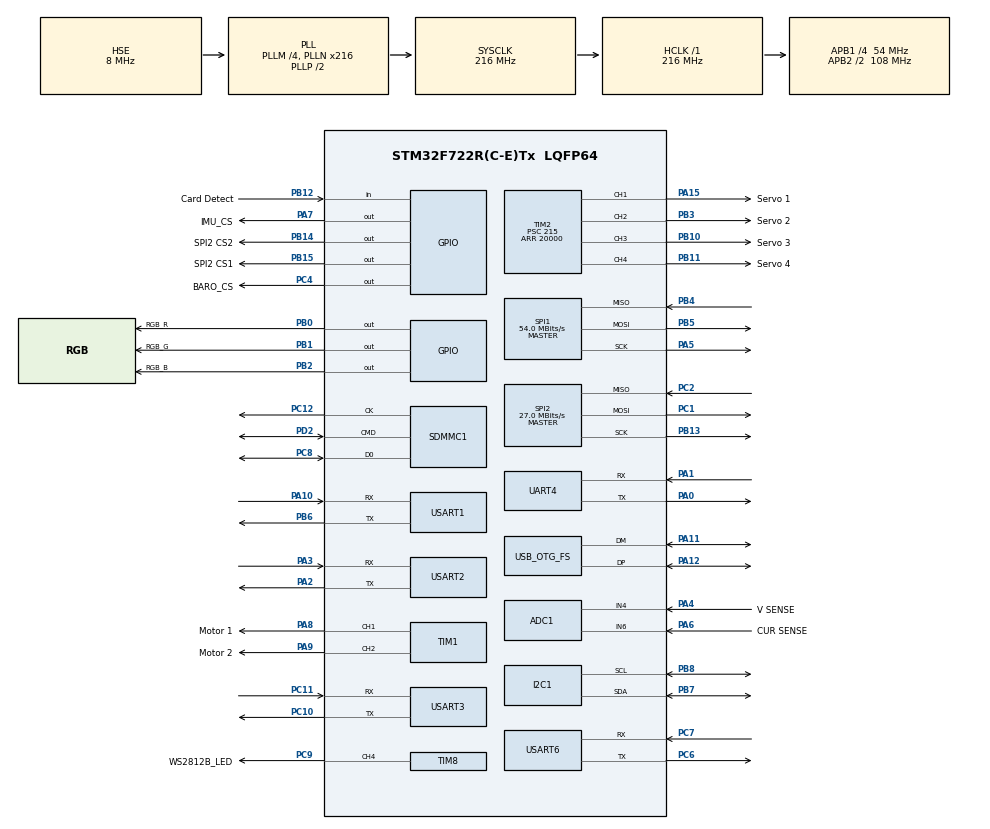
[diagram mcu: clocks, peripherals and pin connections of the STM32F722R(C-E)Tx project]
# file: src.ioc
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ADC1.Channel-1\#ChannelRegularConversion=ADC_CHANNEL_6
ADC1.NbrOfConversionFlag=1
ADC1.Rank-1\#ChannelRegularConversion=1
ADC1.SamplingTime-1\#ChannelRegularConversion=ADC_SAMPLETIME_3CYCLES
ADC1.master=1
CORTEX_M7.default_mode_Activation=1
Dma.I2C1_RX.5.Direction=DMA_PERIPH_TO_MEMORY
Dma.I2C1_RX.5.FIFOMode=DMA_FIFOMODE_DISABLE
Dma.I2C1_RX.5.Instance=DMA1_Stream0
Dma.I2C1_RX.5.MemDataAlignment=DMA_MDATAALIGN_BYTE
Dma.I2C1_RX.5.MemInc=DMA_MINC_ENABLE
Dma.I2C1_RX.5.Mode=DMA_NORMAL
Dma.I2C1_RX.5.PeriphDataAlignment=DMA_PDATAALIGN_BYTE
Dma.I2C1_RX.5.PeriphInc=DMA_PINC_DISABLE
Dma.I2C1_RX.5.Priority=DMA_PRIORITY_LOW
Dma.I2C1_TX.6.Direction=DMA_MEMORY_TO_PERIPH
Dma.I2C1_TX.6.FIFOMode=DMA_FIFOMODE_DISABLE
Dma.I2C1_TX.6.Instance=DMA1_Stream7
Dma.I2C1_TX.6.MemDataAlignment=DMA_MDATAALIGN_BYTE
Dma.I2C1_TX.6.MemInc=DMA_MINC_ENABLE
Dma.I2C1_TX.6.Mode=DMA_NORMAL
Dma.I2C1_TX.6.PeriphDataAlignment=DMA_PDATAALIGN_BYTE
Dma.I2C1_TX.6.PeriphInc=DMA_PINC_DISABLE
Dma.I2C1_TX.6.Priority=DMA_PRIORITY_LOW
Dma.Request0=TIM1_UP
Dma.Request1=USART1_RX
Dma.Request10=SPI1_TX
Dma.Request11=SPI1_RX
Dma.Request2=USART1_TX
Dma.Request3=UART4_RX
Dma.Request4=SDMMC1_TX
Dma.Request5=I2C1_RX
Dma.Request6=I2C1_TX
Dma.Request7=USART2_RX
Dma.Request8=USART2_TX
Dma.Request9=TIM8_UP
Dma.SDMMC1_TX.4.Direction=DMA_MEMORY_TO_PERIPH
Dma.SDMMC1_TX.4.FIFOMode=DMA_FIFOMODE_ENABLE
Dma.SDMMC1_TX.4.FIFOThreshold=DMA_FIFO_THRESHOLD_FULL
Dma.SDMMC1_TX.4.Instance=DMA2_Stream6
Dma.SDMMC1_TX.4.MemBurst=DMA_MBURST_INC4
Dma.SDMMC1_TX.4.MemDataAlignment=DMA_MDATAALIGN_WORD
Dma.SDMMC1_TX.4.MemInc=DMA_MINC_ENABLE
Dma.SDMMC1_TX.4.Mode=DMA_PFCTRL
Dma.SDMMC1_TX.4.PeriphBurst=DMA_PBURST_INC4
Dma.SDMMC1_TX.4.PeriphDataAlignment=DMA_PDATAALIGN_WORD
Dma.SDMMC1_TX.4.PeriphInc=DMA_PINC_DISABLE
Dma.SDMMC1_TX.4.Priority=DMA_PRIORITY_MEDIUM
Dma.SPI1_RX.11.Direction=DMA_PERIPH_TO_MEMORY
Dma.SPI1_RX.11.FIFOMode=DMA_FIFOMODE_DISABLE
Dma.SPI1_RX.11.Instance=DMA2_Stream0
Dma.SPI1_RX.11.MemDataAlignment=DMA_MDATAALIGN_BYTE
Dma.SPI1_RX.11.MemInc=DMA_MINC_ENABLE
Dma.SPI1_RX.11.Mode=DMA_NORMAL
Dma.SPI1_RX.11.PeriphDataAlignment=DMA_PDATAALIGN_BYTE
Dma.SPI1_RX.11.PeriphInc=DMA_PINC_DISABLE
Dma.SPI1_RX.11.Priority=DMA_PRIORITY_VERY_HIGH
Dma.SPI1_TX.10.Direction=DMA_MEMORY_TO_PERIPH
Dma.SPI1_TX.10.FIFOMode=DMA_FIFOMODE_DISABLE
Dma.SPI1_TX.10.Instance=DMA2_Stream3
Dma.SPI1_TX.10.MemDataAlignment=DMA_MDATAALIGN_BYTE
Dma.SPI1_TX.10.MemInc=DMA_MINC_ENABLE
Dma.SPI1_TX.10.Mode=DMA_NORMAL
Dma.SPI1_TX.10.PeriphDataAlignment=DMA_PDATAALIGN_BYTE
Dma.SPI1_TX.10.PeriphInc=DMA_PINC_DISABLE
Dma.SPI1_TX.10.Priority=DMA_PRIORITY_VERY_HIGH
Dma.TIM1_UP.0.Direction=DMA_PERIPH_TO_MEMORY
Dma.TIM1_UP.0.FIFOMode=DMA_FIFOMODE_DISABLE
Dma.TIM1_UP.0.Instance=DMA2_Stream5
Dma.TIM1_UP.0.MemDataAlignment=DMA_MDATAALIGN_HALFWORD
Dma.TIM1_UP.0.MemInc=DMA_MINC_ENABLE
Dma.TIM1_UP.0.Mode=DMA_NORMAL
Dma.TIM1_UP.0.PeriphDataAlignment=DMA_PDATAALIGN_HALFWORD
Dma.TIM1_UP.0.PeriphInc=DMA_PINC_DISABLE
Dma.TIM1_UP.0.Priority=DMA_PRIORITY_HIGH
Dma.TIM8_UP.9.Direction=DMA_PERIPH_TO_MEMORY
Dma.TIM8_UP.9.FIFOMode=DMA_FIFOMODE_DISABLE
Dma.TIM8_UP.9.Instance=DMA2_Stream1
Dma.TIM8_UP.9.MemDataAlignment=DMA_MDATAALIGN_HALFWORD
Dma.TIM8_UP.9.MemInc=DMA_MINC_ENABLE
Dma.TIM8_UP.9.Mode=DMA_NORMAL
Dma.TIM8_UP.9.PeriphDataAlignment=DMA_PDATAALIGN_HALFWORD
Dma.TIM8_UP.9.PeriphInc=DMA_PINC_DISABLE
Dma.TIM8_UP.9.Priority=DMA_PRIORITY_LOW
Dma.UART4_RX.3.Direction=DMA_PERIPH_TO_MEMORY
Dma.UART4_RX.3.FIFOMode=DMA_FIFOMODE_DISABLE
Dma.UART4_RX.3.Instance=DMA1_Stream2
Dma.UART4_RX.3.MemDataAlignment=DMA_MDATAALIGN_BYTE
Dma.UART4_RX.3.MemInc=DMA_MINC_ENABLE
Dma.UART4_RX.3.Mode=DMA_NORMAL
Dma.UART4_RX.3.PeriphDataAlignment=DMA_PDATAALIGN_BYTE
Dma.UART4_RX.3.PeriphInc=DMA_PINC_DISABLE
Dma.UART4_RX.3.Priority=DMA_PRIORITY_MEDIUM
Dma.USART1_RX.1.Direction=DMA_PERIPH_TO_MEMORY
Dma.USART1_RX.1.FIFOMode=DMA_FIFOMODE_DISABLE
Dma.USART1_RX.1.Instance=DMA2_Stream2
Dma.USART1_RX.1.MemDataAlignment=DMA_MDATAALIGN_BYTE
Dma.USART1_RX.1.MemInc=DMA_MINC_ENABLE
Dma.USART1_RX.1.Mode=DMA_NORMAL
Dma.USART1_RX.1.PeriphDataAlignment=DMA_PDATAALIGN_BYTE
Dma.USART1_RX.1.PeriphInc=DMA_PINC_DISABLE
Dma.USART1_RX.1.Priority=DMA_PRIORITY_HIGH
Dma.USART1_TX.2.Direction=DMA_MEMORY_TO_PERIPH
Dma.USART1_TX.2.FIFOMode=DMA_FIFOMODE_DISABLE
Dma.USART1_TX.2.Instance=DMA2_Stream7
Dma.USART1_TX.2.MemDataAlignment=DMA_MDATAALIGN_BYTE
Dma.USART1_TX.2.MemInc=DMA_MINC_ENABLE
Dma.USART1_TX.2.Mode=DMA_NORMAL
Dma.USART1_TX.2.PeriphDataAlignment=DMA_PDATAALIGN_BYTE
Dma.USART1_TX.2.PeriphInc=DMA_PINC_DISABLE
Dma.USART1_TX.2.Priority=DMA_PRIORITY_MEDIUM
Dma.USART2_RX.7.Direction=DMA_PERIPH_TO_MEMORY
Dma.USART2_RX.7.FIFOMode=DMA_FIFOMODE_DISABLE
Dma.USART2_RX.7.Instance=DMA1_Stream5
Dma.USART2_RX.7.MemDataAlignment=DMA_MDATAALIGN_BYTE
Dma.USART2_RX.7.MemInc=DMA_MINC_ENABLE
Dma.USART2_RX.7.Mode=DMA_NORMAL
Dma.USART2_RX.7.PeriphDataAlignment=DMA_PDATAALIGN_BYTE
Dma.USART2_RX.7.PeriphInc=DMA_PINC_DISABLE
Dma.USART2_RX.7.Priority=DMA_PRIORITY_LOW
Dma.USART2_TX.8.Direction=DMA_MEMORY_TO_PERIPH
Dma.USART2_TX.8.FIFOMode=DMA_FIFOMODE_DISABLE
Dma.USART2_TX.8.Instance=DMA1_Stream6
Dma.USART2_TX.8.MemDataAlignment=DMA_MDATAALIGN_BYTE
Dma.USART2_TX.8.MemInc=DMA_MINC_ENABLE
Dma.USART2_TX.8.Mode=DMA_NORMAL
Dma.USART2_TX.8.PeriphDataAlignment=DMA_PDATAALIGN_BYTE
Dma.USART2_TX.8.PeriphInc=DMA_PINC_DISABLE
Dma.USART2_TX.8.Priority=DMA_PRIORITY_LOW
I2C1.Timing=0x20404768
Mcu.Family=STM32F7
Mcu.Name=STM32F722R(C-E)Tx
Mcu.Package=LQFP64
NVIC.DMA1_Stream0_IRQn=true\:0\:0\:false\:false\:true\:false\:true\:true
NVIC.DMA1_Stream2_IRQn=true\:0\:0\:false\:false\:true\:false\:true\:true
NVIC.DMA1_Stream5_IRQn=true\:0\:0\:false\:false\:true\:false\:true\:true
NVIC.DMA1_Stream6_IRQn=true\:0\:0\:false\:false\:true\:false\:true\:true
NVIC.DMA1_Stream7_IRQn=true\:0\:0\:false\:false\:true\:false\:true\:true
NVIC.DMA2_Stream0_IRQn=true\:0\:0\:false\:false\:true\:false\:true\:true
NVIC.DMA2_Stream1_IRQn=true\:0\:0\:false\:false\:true\:false\:true\:true
NVIC.DMA2_Stream2_IRQn=true\:0\:0\:false\:false\:true\:false\:true\:true
NVIC.DMA2_Stream3_IRQn=true\:0\:0\:false\:false\:true\:false\:true\:true
NVIC.DMA2_Stream5_IRQn=true\:0\:0\:false\:false\:true\:false\:true\:true
NVIC.DMA2_Stream6_IRQn=true\:0\:0\:false\:false\:true\:false\:true\:true
NVIC.DMA2_Stream7_IRQn=true\:0\:0\:false\:false\:true\:false\:true\:true
NVIC.OTG_FS_IRQn=true\:0\:0\:false\:false\:true\:false\:true\:true
NVIC.PriorityGroup=NVIC_PRIORITYGROUP_4
NVIC.USART1_IRQn=true\:0\:0\:false\:false\:true\:false\:true\:true
NVIC.USART2_IRQn=true\:0\:0\:false\:false\:true\:false\:true\:true
PA0-WKUP.Mode=Asynchronous
PA0-WKUP.Signal=UART4_TX
PA1.Mode=Asynchronous
PA1.Signal=UART4_RX
PA10.Mode=Asynchronous
PA10.Signal=USART1_RX
PA11.Mode=Device_Only
PA11.Signal=USB_OTG_FS_DM
PA12.Mode=Device_Only
PA12.Signal=USB_OTG_FS_DP
PA13.Mode=Serial_Wire
PA13.Signal=SYS_JTMS-SWDIO
PA14.Mode=Serial_Wire
PA14.Signal=SYS_JTCK-SWCLK
PA15.GPIO_Label=Servo 1
PA15.Signal=S_TIM2_CH1_ETR
PA2.Mode=Asynchronous
PA2.Signal=USART2_TX
PA3.Mode=Asynchronous
PA3.Signal=USART2_RX
PA4.GPIO_Label=V SENSE
PA4.Signal=ADCx_IN4
PA5.Mode=Full_Duplex_Master
PA5.Signal=SPI1_SCK
PA6.GPIO_Label=CUR SENSE
PA6.Signal=ADCx_IN6
PA7.GPIO_Label=IMU_CS
PA7.Signal=GPIO_Output
PA8.GPIO_Label=Motor 1
PA8.Signal=S_TIM1_CH1
PA9.GPIO_Label=Motor 2
PA9.Signal=S_TIM1_CH2
PB0.GPIO_Label=RGB_R
PB0.Signal=GPIO_Output
PB1.GPIO_Label=RGB_G
PB1.Signal=GPIO_Output
PB10.GPIO_Label=Servo 3
PB10.Signal=S_TIM2_CH3
PB11.GPIO_Label=Servo 4
PB11.Signal=S_TIM2_CH4
PB12.GPIO_Label=Card Detect
PB12.Signal=GPIO_Input
PB13.Mode=Full_Duplex_Master
PB13.Signal=SPI2_SCK
PB14.GPIO_Label=SPI2 CS2
PB14.Signal=GPIO_Output
PB15.GPIO_Label=SPI2 CS1
PB15.Signal=GPIO_Output
PB2.GPIO_Label=RGB_B
PB2.Signal=GPIO_Output
PB3.GPIO_Label=Servo 2
PB3.Signal=S_TIM2_CH2
PB4.Mode=Full_Duplex_Master
PB4.Signal=SPI1_MISO
PB5.Mode=Full_Duplex_Master
PB5.Signal=SPI1_MOSI
PB6.Mode=Asynchronous
PB6.Signal=USART1_TX
PB7.Mode=I2C
PB7.Signal=I2C1_SDA
PB8.Mode=I2C
PB8.Signal=I2C1_SCL
PC1.Mode=Full_Duplex_Master
PC1.Signal=SPI2_MOSI
PC10.Mode=Asynchronous
PC10.Signal=USART3_TX
PC11.Mode=Asynchronous
PC11.Signal=USART3_RX
PC12.Mode=SD_1_bit
PC12.Signal=SDMMC1_CK
PC2.Mode=Full_Duplex_Master
PC2.Signal=SPI2_MISO
PC4.GPIO_Label=BARO_CS
PC4.Signal=GPIO_Output
PC6.Mode=Asynchronous
PC6.Signal=USART6_TX
PC7.Mode=Asynchronous
PC7.Signal=USART6_RX
PC8.Mode=SD_1_bit
PC8.Signal=SDMMC1_D0
PC9.GPIO_Label=WS2812B_LED
PC9.Signal=S_TIM8_CH4
PD2.Mode=SD_1_bit
PD2.Signal=SDMMC1_CMD
PH0-OSC_IN.Mode=HSE-External-Clock-Source
PH0-OSC_IN.Signal=RCC_OSC_IN
PH1-OSC_OUT.Mode=HSE-External-Clock-Source
PH1-OSC_OUT.Signal=RCC_OSC_OUT
ProjectManager.HeapSize=0x200
ProjectManager.StackSize=0x400
ProjectManager.TargetToolchain=CMake
RCC.AHBFreq_Value=216000000
RCC.APB1CLKDivider=RCC_HCLK_DIV4
RCC.APB1Freq_Value=54000000
RCC.APB1TimFreq_Value=108000000
RCC.APB2CLKDivider=RCC_HCLK_DIV2
RCC.APB2Freq_Value=108000000
RCC.APB2TimFreq_Value=216000000
RCC.CortexFreq_Value=216000000
RCC.EnbaleCSS=true
RCC.HCLKFreq_Value=216000000
RCC.HSE_VALUE=8000000
RCC.HSI_VALUE=16000000
RCC.LSE_VALUE=32768
RCC.PLLM=4
RCC.PLLN=216
RCC.PLLQ=9
RCC.SDMMCClockSelection=RCC_SDMMC1CLKSOURCE_CLK48
RCC.SYSCLKFreq_VALUE=216000000
RCC.SYSCLKSource=RCC_SYSCLKSOURCE_PLLCLK
RCC.USBFreq_Value=48000000
RCC.VCOOutputFreq_Value=432000000
SH.ADCx_IN4.0=ADC1_IN4,IN4
SH.ADCx_IN6.0=ADC1_IN6,IN6
SH.S_TIM1_CH1.0=TIM1_CH1,Output Compare1 CH1
SH.S_TIM1_CH2.0=TIM1_CH2,Output Compare2 CH2
SH.S_TIM2_CH1_ETR.0=TIM2_CH1,Output Compare1 CH1
SH.S_TIM2_CH2.0=TIM2_CH2,Output Compare2 CH2
SH.S_TIM2_CH3.0=TIM2_CH3,Output Compare3 CH3
SH.S_TIM2_CH4.0=TIM2_CH4,Output Compare4 CH4
SH.S_TIM8_CH4.0=TIM8_CH4,Output Compare4 CH4
SPI1.BaudRatePrescaler=SPI_BAUDRATEPRESCALER_2
SPI1.CalculateBaudRate=54.0 MBits/s
SPI1.Direction=SPI_DIRECTION_2LINES
SPI1.Mode=SPI_MODE_MASTER
SPI1.VirtualType=VM_MASTER
SPI2.BaudRatePrescaler=SPI_BAUDRATEPRESCALER_2
SPI2.CalculateBaudRate=27.0 MBits/s
SPI2.Direction=SPI_DIRECTION_2LINES
SPI2.Mode=SPI_MODE_MASTER
SPI2.VirtualType=VM_MASTER
TIM1.Channel-Output\ Compare1\ CH1=TIM_CHANNEL_1
TIM1.Channel-Output\ Compare2\ CH2=TIM_CHANNEL_2
TIM2.Channel-Output\ Compare1\ CH1=TIM_CHANNEL_1
TIM2.Channel-Output\ Compare2\ CH2=TIM_CHANNEL_2
TIM2.Channel-Output\ Compare3\ CH3=TIM_CHANNEL_3
TIM2.Channel-Output\ Compare4\ CH4=TIM_CHANNEL_4
TIM2.Period=20000
TIM2.Prescaler=215
TIM5.Prescaler=215
TIM8.Channel-Output\ Compare4\ CH4=TIM_CHANNEL_4
USART1.VirtualMode-Asynchronous=VM_ASYNC
USART2.VirtualMode-Asynchronous=VM_ASYNC
USART3.VirtualMode-Asynchronous=VM_ASYNC
USART6.VirtualMode=VM_ASYNC
USB_DEVICE.CLASS_NAME_FS=CDC
USB_DEVICE.VirtualMode-CDC_FS=Cdc
USB_DEVICE.VirtualModeFS=Cdc_FS
USB_OTG_FS.VirtualMode=Device_Only
VP_CRC_VS_CRC.Mode=CRC_Activate
VP_TIM2_VS_ClockSourceINT.Mode=Internal
VP_TIM5_VS_ClockSourceINT.Mode=Internal
VP_TIM8_VS_ClockSourceINT.Mode=Internal
VP_USB_DEVICE_VS_USB_DEVICE_CDC_FS.Mode=CDC_FS
board=custom

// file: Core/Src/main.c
/* USER CODE BEGIN Header */
/**
  ******************************************************************************
  * @file           : main.c
  * @brief          : Main program body
  ******************************************************************************
  * @attention
  *
  * Copyright (c) 2026 STMicroelectronics.
  * All rights reserved.
  *
  * This software is licensed under terms that can be found in the LICENSE file
  * in the root directory of this software component.
  * If no LICENSE file comes with this software, it is provided AS-IS.
  *
  ******************************************************************************
  */
/* USER CODE END Header */
#include "main.h"
#include "usb_device.h"

/* USER CODE BEGIN Includes */
#include "time-utils.h"
#include "sd.h"
/* USER CODE END Includes */

ADC_HandleTypeDef hadc1;

CRC_HandleTypeDef hcrc;

I2C_HandleTypeDef hi2c1;
DMA_HandleTypeDef hdma_i2c1_rx;
DMA_HandleTypeDef hdma_i2c1_tx;

SD_HandleTypeDef hsd1;
DMA_HandleTypeDef hdma_sdmmc1_tx;

SPI_HandleTypeDef hspi2;

TIM_HandleTypeDef htim1;
TIM_HandleTypeDef htim2;
TIM_HandleTypeDef htim5;
TIM_HandleTypeDef htim8;
DMA_HandleTypeDef hdma_tim1_up;
DMA_HandleTypeDef hdma_tim8_up;

UART_HandleTypeDef huart4;
UART_HandleTypeDef huart1;
UART_HandleTypeDef huart2;
UART_HandleTypeDef huart3;
UART_HandleTypeDef huart6;
DMA_HandleTypeDef hdma_uart4_rx;
DMA_HandleTypeDef hdma_usart1_rx;
DMA_HandleTypeDef hdma_usart1_tx;
DMA_HandleTypeDef hdma_usart2_rx;
DMA_HandleTypeDef hdma_usart2_tx;

void SystemClock_Config(void);
static void MPU_Config(void);
static void MX_GPIO_Init(void);
static void MX_DMA_Init(void);
static void MX_CRC_Init(void);
static void MX_I2C1_Init(void);
static void MX_SDMMC1_SD_Init(void);
static void MX_SPI1_Init(void);
static void MX_SPI2_Init(void);
static void MX_TIM1_Init(void);
static void MX_TIM2_Init(void);
static void MX_TIM5_Init(void);
static void MX_UART4_Init(void);
static void MX_USART1_UART_Init(void);
static void MX_USART2_UART_Init(void);
static void MX_USART3_UART_Init(void);
static void MX_USART6_UART_Init(void);
static void MX_ADC1_Init(void);
static void MX_TIM8_Init(void);

int main(void)
{

  /* MPU Configuration--------------------------------------------------------*/
  MPU_Config();

  /* MCU Configuration--------------------------------------------------------*/

  /* Reset of all peripherals, Initializes the Flash interface and the Systick. */
  HAL_Init();

  /* Configure the system clock */
  SystemClock_Config();

  /* Initialize all configured peripherals */
  MX_GPIO_Init();
  MX_DMA_Init();
  MX_CRC_Init();
  MX_I2C1_Init();
  MX_SDMMC1_SD_Init();
  MX_SPI1_Init();
  MX_SPI2_Init();
  MX_TIM1_Init();
  MX_TIM2_Init();
  MX_TIM5_Init();
  MX_UART4_Init();
  MX_USART1_UART_Init();
  MX_USART2_UART_Init();
  MX_USART3_UART_Init();
  MX_USART6_UART_Init();
  MX_USB_DEVICE_Init();
  MX_ADC1_Init();
  MX_TIM8_Init();
  /* USER CODE BEGIN 2 */

  TIME_UTILS_MICROS_TIM_START(&htim5);

  /* USER CODE END 2 */

  /* Infinite loop */
  /* USER CODE BEGIN WHILE */
  while (1)
  {
    uint8_t buffer[512] = {0};
    SD_READ_BLOCK(buffer, 99);
    /* USER CODE END WHILE */

  }
}

void SystemClock_Config(void)
{
  RCC_OscInitTypeDef RCC_OscInitStruct = {0};
  RCC_ClkInitTypeDef RCC_ClkInitStruct = {0};

  /** Configure the main internal regulator output voltage
  */
  __HAL_RCC_PWR_CLK_ENABLE();
  __HAL_PWR_VOLTAGESCALING_CONFIG(PWR_REGULATOR_VOLTAGE_SCALE1);

  /** Initializes the RCC Oscillators according to the specified parameters
  * in the RCC_OscInitTypeDef structure.
  */
  RCC_OscInitStruct.OscillatorType = RCC_OSCILLATORTYPE_HSE;
  RCC_OscInitStruct.HSEState = RCC_HSE_BYPASS;
  RCC_OscInitStruct.PLL.PLLState = RCC_PLL_ON;
  RCC_OscInitStruct.PLL.PLLSource = RCC_PLLSOURCE_HSE;
  RCC_OscInitStruct.PLL.PLLM = 4;
  RCC_OscInitStruct.PLL.PLLN = 216;
  RCC_OscInitStruct.PLL.PLLP = RCC_PLLP_DIV2;
  RCC_OscInitStruct.PLL.PLLQ = 9;
  if (HAL_RCC_OscConfig(&RCC_OscInitStruct) != HAL_OK)
  {
    Error_Handler();
  }

  /** Activate the Over-Drive mode
  */
  if (HAL_PWREx_EnableOverDrive() != HAL_OK)
  {
    Error_Handler();
  }

  /** Initializes the CPU, AHB and APB buses clocks
  */
  RCC_ClkInitStruct.ClockType = RCC_CLOCKTYPE_HCLK|RCC_CLOCKTYPE_SYSCLK
                              |RCC_CLOCKTYPE_PCLK1|RCC_CLOCKTYPE_PCLK2;
  RCC_ClkInitStruct.SYSCLKSource = RCC_SYSCLKSOURCE_PLLCLK;
  RCC_ClkInitStruct.AHBCLKDivider = RCC_SYSCLK_DIV1;
  RCC_ClkInitStruct.APB1CLKDivider = RCC_HCLK_DIV4;
  RCC_ClkInitStruct.APB2CLKDivider = RCC_HCLK_DIV2;

  if (HAL_RCC_ClockConfig(&RCC_ClkInitStruct, FLASH_LATENCY_7) != HAL_OK)
  {
    Error_Handler();
  }

  /** Enables the Clock Security System
  */
  HAL_RCC_EnableCSS();
}

static void MX_ADC1_Init(void)
{

  ADC_ChannelConfTypeDef sConfig = {0};

  /** Configure the global features of the ADC (Clock, Resolution, Data Alignment and number of conversion)
  */
  hadc1.Instance = ADC1;
  hadc1.Init.ClockPrescaler = ADC_CLOCK_SYNC_PCLK_DIV4;
  hadc1.Init.Resolution = ADC_RESOLUTION_12B;
  hadc1.Init.ScanConvMode = ADC_SCAN_DISABLE;
  hadc1.Init.ContinuousConvMode = DISABLE;
  hadc1.Init.DiscontinuousConvMode = DISABLE;
  hadc1.Init.ExternalTrigConvEdge = ADC_EXTERNALTRIGCONVEDGE_NONE;
  hadc1.Init.ExternalTrigConv = ADC_SOFTWARE_START;
  hadc1.Init.DataAlign = ADC_DATAALIGN_RIGHT;
  hadc1.Init.NbrOfConversion = 1;
  hadc1.Init.DMAContinuousRequests = DISABLE;
  hadc1.Init.EOCSelection = ADC_EOC_SINGLE_CONV;
  if (HAL_ADC_Init(&hadc1) != HAL_OK)
  {
    Error_Handler();
  }

  /** Configure for the selected ADC regular channel its corresponding rank in the sequencer and its sample time.
  */
  sConfig.Channel = ADC_CHANNEL_6;
  sConfig.Rank = ADC_REGULAR_RANK_1;
  sConfig.SamplingTime = ADC_SAMPLETIME_3CYCLES;
  if (HAL_ADC_ConfigChannel(&hadc1, &sConfig) != HAL_OK)
  {
    Error_Handler();
  }

}

static void MX_CRC_Init(void)
{

  hcrc.Instance = CRC;
  hcrc.Init.DefaultPolynomialUse = DEFAULT_POLYNOMIAL_ENABLE;
  hcrc.Init.DefaultInitValueUse = DEFAULT_INIT_VALUE_ENABLE;
  hcrc.Init.InputDataInversionMode = CRC_INPUTDATA_INVERSION_NONE;
  hcrc.Init.OutputDataInversionMode = CRC_OUTPUTDATA_INVERSION_DISABLE;
  hcrc.InputDataFormat = CRC_INPUTDATA_FORMAT_BYTES;
  if (HAL_CRC_Init(&hcrc) != HAL_OK)
  {
    Error_Handler();
  }

}

static void MX_I2C1_Init(void)
{

  hi2c1.Instance = I2C1;
  hi2c1.Init.Timing = 0x20404768;
  hi2c1.Init.OwnAddress1 = 0;
  hi2c1.Init.AddressingMode = I2C_ADDRESSINGMODE_7BIT;
  hi2c1.Init.DualAddressMode = I2C_DUALADDRESS_DISABLE;
  hi2c1.Init.OwnAddress2 = 0;
  hi2c1.Init.OwnAddress2Masks = I2C_OA2_NOMASK;
  hi2c1.Init.GeneralCallMode = I2C_GENERALCALL_DISABLE;
  hi2c1.Init.NoStretchMode = I2C_NOSTRETCH_DISABLE;
  if (HAL_I2C_Init(&hi2c1) != HAL_OK)
  {
    Error_Handler();
  }

  /** Configure Analogue filter
  */
  if (HAL_I2CEx_ConfigAnalogFilter(&hi2c1, I2C_ANALOGFILTER_ENABLE) != HAL_OK)
  {
    Error_Handler();
  }

  /** Configure Digital filter
  */
  if (HAL_I2CEx_ConfigDigitalFilter(&hi2c1, 0) != HAL_OK)
  {
    Error_Handler();
  }

}

static void MX_SDMMC1_SD_Init(void)
{

  hsd1.Instance = SDMMC1;
  hsd1.Init.ClockEdge = SDMMC_CLOCK_EDGE_RISING;
  hsd1.Init.ClockBypass = SDMMC_CLOCK_BYPASS_DISABLE;
  hsd1.Init.ClockPowerSave = SDMMC_CLOCK_POWER_SAVE_DISABLE;
  hsd1.Init.BusWide = SDMMC_BUS_WIDE_1B;
  hsd1.Init.HardwareFlowControl = SDMMC_HARDWARE_FLOW_CONTROL_DISABLE;
  hsd1.Init.ClockDiv = 0;
  if (HAL_SD_Init(&hsd1) != HAL_OK)
  {
    Error_Handler();
  }

}

static void MX_SPI1_Init(void)
{

  LL_SPI_InitTypeDef SPI_InitStruct = {0};

  LL_GPIO_InitTypeDef GPIO_InitStruct = {0};

  /* Peripheral clock enable */
  LL_APB2_GRP1_EnableClock(LL_APB2_GRP1_PERIPH_SPI1);

  LL_AHB1_GRP1_EnableClock(LL_AHB1_GRP1_PERIPH_GPIOA);
  LL_AHB1_GRP1_EnableClock(LL_AHB1_GRP1_PERIPH_GPIOB);
  /**SPI1 GPIO Configuration
  PA5   ------> SPI1_SCK
  PB4   ------> SPI1_MISO
  PB5   ------> SPI1_MOSI
  */
  GPIO_InitStruct.Pin = LL_GPIO_PIN_5;
  GPIO_InitStruct.Mode = LL_GPIO_MODE_ALTERNATE;
  GPIO_InitStruct.Speed = LL_GPIO_SPEED_FREQ_VERY_HIGH;
  GPIO_InitStruct.OutputType = LL_GPIO_OUTPUT_PUSHPULL;
  GPIO_InitStruct.Pull = LL_GPIO_PULL_NO;
  GPIO_InitStruct.Alternate = LL_GPIO_AF_5;
  LL_GPIO_Init(GPIOA, &GPIO_InitStruct);

  GPIO_InitStruct.Pin = LL_GPIO_PIN_4;
  GPIO_InitStruct.Mode = LL_GPIO_MODE_ALTERNATE;
  GPIO_InitStruct.Speed = LL_GPIO_SPEED_FREQ_VERY_HIGH;
  GPIO_InitStruct.OutputType = LL_GPIO_OUTPUT_PUSHPULL;
  GPIO_InitStruct.Pull = LL_GPIO_PULL_NO;
  GPIO_InitStruct.Alternate = LL_GPIO_AF_5;
  LL_GPIO_Init(GPIOB, &GPIO_InitStruct);

  GPIO_InitStruct.Pin = LL_GPIO_PIN_5;
  GPIO_InitStruct.Mode = LL_GPIO_MODE_ALTERNATE;
  GPIO_InitStruct.Speed = LL_GPIO_SPEED_FREQ_VERY_HIGH;
  GPIO_InitStruct.OutputType = LL_GPIO_OUTPUT_PUSHPULL;
  GPIO_InitStruct.Pull = LL_GPIO_PULL_NO;
  GPIO_InitStruct.Alternate = LL_GPIO_AF_5;
  LL_GPIO_Init(GPIOB, &GPIO_InitStruct);

  /* SPI1 DMA Init */

  /* SPI1_TX Init */
  LL_DMA_SetChannelSelection(DMA2, LL_DMA_STREAM_3, LL_DMA_CHANNEL_3);

  LL_DMA_SetDataTransferDirection(DMA2, LL_DMA_STREAM_3, LL_DMA_DIRECTION_MEMORY_TO_PERIPH);

  LL_DMA_SetStreamPriorityLevel(DMA2, LL_DMA_STREAM_3, LL_DMA_PRIORITY_VERYHIGH);

  LL_DMA_SetMode(DMA2, LL_DMA_STREAM_3, LL_DMA_MODE_NORMAL);

  LL_DMA_SetPeriphIncMode(DMA2, LL_DMA_STREAM_3, LL_DMA_PERIPH_NOINCREMENT);

  LL_DMA_SetMemoryIncMode(DMA2, LL_DMA_STREAM_3, LL_DMA_MEMORY_INCREMENT);

  LL_DMA_SetPeriphSize(DMA2, LL_DMA_STREAM_3, LL_DMA_PDATAALIGN_BYTE);

  LL_DMA_SetMemorySize(DMA2, LL_DMA_STREAM_3, LL_DMA_MDATAALIGN_BYTE);

  LL_DMA_DisableFifoMode(DMA2, LL_DMA_STREAM_3);

  /* SPI1_RX Init */
  LL_DMA_SetChannelSelection(DMA2, LL_DMA_STREAM_0, LL_DMA_CHANNEL_3);

  LL_DMA_SetDataTransferDirection(DMA2, LL_DMA_STREAM_0, LL_DMA_DIRECTION_PERIPH_TO_MEMORY);

  LL_DMA_SetStreamPriorityLevel(DMA2, LL_DMA_STREAM_0, LL_DMA_PRIORITY_VERYHIGH);

  LL_DMA_SetMode(DMA2, LL_DMA_STREAM_0, LL_DMA_MODE_NORMAL);

  LL_DMA_SetPeriphIncMode(DMA2, LL_DMA_STREAM_0, LL_DMA_PERIPH_NOINCREMENT);

  LL_DMA_SetMemoryIncMode(DMA2, LL_DMA_STREAM_0, LL_DMA_MEMORY_INCREMENT);

  LL_DMA_SetPeriphSize(DMA2, LL_DMA_STREAM_0, LL_DMA_PDATAALIGN_BYTE);

  LL_DMA_SetMemorySize(DMA2, LL_DMA_STREAM_0, LL_DMA_MDATAALIGN_BYTE);

  LL_DMA_DisableFifoMode(DMA2, LL_DMA_STREAM_0);

  /* SPI1 parameter configuration*/
  SPI_InitStruct.TransferDirection = LL_SPI_FULL_DUPLEX;
  SPI_InitStruct.Mode = LL_SPI_MODE_MASTER;
  SPI_InitStruct.DataWidth = LL_SPI_DATAWIDTH_4BIT;
  SPI_InitStruct.ClockPolarity = LL_SPI_POLARITY_LOW;
  SPI_InitStruct.ClockPhase = LL_SPI_PHASE_1EDGE;
  SPI_InitStruct.NSS = LL_SPI_NSS_SOFT;
  SPI_InitStruct.BaudRate = LL_SPI_BAUDRATEPRESCALER_DIV2;
  SPI_InitStruct.BitOrder = LL_SPI_MSB_FIRST;
  SPI_InitStruct.CRCCalculation = LL_SPI_CRCCALCULATION_DISABLE;
  SPI_InitStruct.CRCPoly = 7;
  LL_SPI_Init(SPI1, &SPI_InitStruct);
  LL_SPI_SetStandard(SPI1, LL_SPI_PROTOCOL_MOTOROLA);
  LL_SPI_EnableNSSPulseMgt(SPI1);

}

static void MX_SPI2_Init(void)
{

  /* SPI2 parameter configuration*/
  hspi2.Instance = SPI2;
  hspi2.Init.Mode = SPI_MODE_MASTER;
  hspi2.Init.Direction = SPI_DIRECTION_2LINES;
  hspi2.Init.DataSize = SPI_DATASIZE_4BIT;
  hspi2.Init.CLKPolarity = SPI_POLARITY_LOW;
  hspi2.Init.CLKPhase = SPI_PHASE_1EDGE;
  hspi2.Init.NSS = SPI_NSS_SOFT;
  hspi2.Init.BaudRatePrescaler = SPI_BAUDRATEPRESCALER_2;
  hspi2.Init.FirstBit = SPI_FIRSTBIT_MSB;
  hspi2.Init.TIMode = SPI_TIMODE_DISABLE;
  hspi2.Init.CRCCalculation = SPI_CRCCALCULATION_DISABLE;
  hspi2.Init.CRCPolynomial = 7;
  hspi2.Init.CRCLength = SPI_CRC_LENGTH_DATASIZE;
  hspi2.Init.NSSPMode = SPI_NSS_PULSE_ENABLE;
  if (HAL_SPI_Init(&hspi2) != HAL_OK)
  {
    Error_Handler();
  }

}

static void MX_TIM1_Init(void)
{

  TIM_MasterConfigTypeDef sMasterConfig = {0};
  TIM_OC_InitTypeDef sConfigOC = {0};
  TIM_BreakDeadTimeConfigTypeDef sBreakDeadTimeConfig = {0};

  htim1.Instance = TIM1;
  htim1.Init.Prescaler = 0;
  htim1.Init.CounterMode = TIM_COUNTERMODE_UP;
  htim1.Init.Period = 65535;
  htim1.Init.ClockDivision = TIM_CLOCKDIVISION_DIV1;
  htim1.Init.RepetitionCounter = 0;
  htim1.Init.AutoReloadPreload = TIM_AUTORELOAD_PRELOAD_DISABLE;
  if (HAL_TIM_OC_Init(&htim1) != HAL_OK)
  {
    Error_Handler();
  }
  sMasterConfig.MasterOutputTrigger = TIM_TRGO_RESET;
  sMasterConfig.MasterOutputTrigger2 = TIM_TRGO2_RESET;
  sMasterConfig.MasterSlaveMode = TIM_MASTERSLAVEMODE_DISABLE;
  if (HAL_TIMEx_MasterConfigSynchronization(&htim1, &sMasterConfig) != HAL_OK)
  {
    Error_Handler();
  }
  sConfigOC.OCMode = TIM_OCMODE_TIMING;
  sConfigOC.Pulse = 0;
  sConfigOC.OCPolarity = TIM_OCPOLARITY_HIGH;
  sConfigOC.OCNPolarity = TIM_OCNPOLARITY_HIGH;
  sConfigOC.OCFastMode = TIM_OCFAST_DISABLE;
  sConfigOC.OCIdleState = TIM_OCIDLESTATE_RESET;
  sConfigOC.OCNIdleState = TIM_OCNIDLESTATE_RESET;
  if (HAL_TIM_OC_ConfigChannel(&htim1, &sConfigOC, TIM_CHANNEL_1) != HAL_OK)
  {
    Error_Handler();
  }
  if (HAL_TIM_OC_ConfigChannel(&htim1, &sConfigOC, TIM_CHANNEL_2) != HAL_OK)
  {
    Error_Handler();
  }
  sBreakDeadTimeConfig.OffStateRunMode = TIM_OSSR_DISABLE;
  sBreakDeadTimeConfig.OffStateIDLEMode = TIM_OSSI_DISABLE;
  sBreakDeadTimeConfig.LockLevel = TIM_LOCKLEVEL_OFF;
  sBreakDeadTimeConfig.DeadTime = 0;
  sBreakDeadTimeConfig.BreakState = TIM_BREAK_DISABLE;
  sBreakDeadTimeConfig.BreakPolarity = TIM_BREAKPOLARITY_HIGH;
  sBreakDeadTimeConfig.BreakFilter = 0;
  sBreakDeadTimeConfig.Break2State = TIM_BREAK2_DISABLE;
  sBreakDeadTimeConfig.Break2Polarity = TIM_BREAK2POLARITY_HIGH;
  sBreakDeadTimeConfig.Break2Filter = 0;
  sBreakDeadTimeConfig.AutomaticOutput = TIM_AUTOMATICOUTPUT_DISABLE;
  if (HAL_TIMEx_ConfigBreakDeadTime(&htim1, &sBreakDeadTimeConfig) != HAL_OK)
  {
    Error_Handler();
  }
  HAL_TIM_MspPostInit(&htim1);

}

static void MX_TIM2_Init(void)
{

  TIM_ClockConfigTypeDef sClockSourceConfig = {0};
  TIM_MasterConfigTypeDef sMasterConfig = {0};
  TIM_OC_InitTypeDef sConfigOC = {0};

  htim2.Instance = TIM2;
  htim2.Init.Prescaler = 215;
  htim2.Init.CounterMode = TIM_COUNTERMODE_UP;
  htim2.Init.Period = 20000;
  htim2.Init.ClockDivision = TIM_CLOCKDIVISION_DIV1;
  htim2.Init.AutoReloadPreload = TIM_AUTORELOAD_PRELOAD_DISABLE;
  if (HAL_TIM_Base_Init(&htim2) != HAL_OK)
  {
    Error_Handler();
  }
  sClockSourceConfig.ClockSource = TIM_CLOCKSOURCE_INTERNAL;
  if (HAL_TIM_ConfigClockSource(&htim2, &sClockSourceConfig) != HAL_OK)
  {
    Error_Handler();
  }
  if (HAL_TIM_OC_Init(&htim2) != HAL_OK)
  {
    Error_Handler();
  }
  sMasterConfig.MasterOutputTrigger = TIM_TRGO_RESET;
  sMasterConfig.MasterSlaveMode = TIM_MASTERSLAVEMODE_DISABLE;
  if (HAL_TIMEx_MasterConfigSynchronization(&htim2, &sMasterConfig) != HAL_OK)
  {
    Error_Handler();
  }
  sConfigOC.OCMode = TIM_OCMODE_TIMING;
  sConfigOC.Pulse = 0;
  sConfigOC.OCPolarity = TIM_OCPOLARITY_HIGH;
  sConfigOC.OCFastMode = TIM_OCFAST_DISABLE;
  if (HAL_TIM_OC_ConfigChannel(&htim2, &sConfigOC, TIM_CHANNEL_1) != HAL_OK)
  {
    Error_Handler();
  }
  if (HAL_TIM_OC_ConfigChannel(&htim2, &sConfigOC, TIM_CHANNEL_2) != HAL_OK)
  {
    Error_Handler();
  }
  if (HAL_TIM_OC_ConfigChannel(&htim2, &sConfigOC, TIM_CHANNEL_3) != HAL_OK)
  {
    Error_Handler();
  }
  if (HAL_TIM_OC_ConfigChannel(&htim2, &sConfigOC, TIM_CHANNEL_4) != HAL_OK)
  {
    Error_Handler();
  }
  HAL_TIM_MspPostInit(&htim2);

}

static void MX_TIM5_Init(void)
{

  TIM_ClockConfigTypeDef sClockSourceConfig = {0};
  TIM_MasterConfigTypeDef sMasterConfig = {0};

  htim5.Instance = TIM5;
  htim5.Init.Prescaler = 215;
  htim5.Init.CounterMode = TIM_COUNTERMODE_UP;
  htim5.Init.Period = 4294967295;
  htim5.Init.ClockDivision = TIM_CLOCKDIVISION_DIV1;
  htim5.Init.AutoReloadPreload = TIM_AUTORELOAD_PRELOAD_DISABLE;
  if (HAL_TIM_Base_Init(&htim5) != HAL_OK)
  {
    Error_Handler();
  }
  sClockSourceConfig.ClockSource = TIM_CLOCKSOURCE_INTERNAL;
  if (HAL_TIM_ConfigClockSource(&htim5, &sClockSourceConfig) != HAL_OK)
  {
    Error_Handler();
  }
  sMasterConfig.MasterOutputTrigger = TIM_TRGO_RESET;
  sMasterConfig.MasterSlaveMode = TIM_MASTERSLAVEMODE_DISABLE;
  if (HAL_TIMEx_MasterConfigSynchronization(&htim5, &sMasterConfig) != HAL_OK)
  {
    Error_Handler();
  }

}

static void MX_TIM8_Init(void)
{

  TIM_ClockConfigTypeDef sClockSourceConfig = {0};
  TIM_MasterConfigTypeDef sMasterConfig = {0};
  TIM_OC_InitTypeDef sConfigOC = {0};
  TIM_BreakDeadTimeConfigTypeDef sBreakDeadTimeConfig = {0};

  htim8.Instance = TIM8;
  htim8.Init.Prescaler = 0;
  htim8.Init.CounterMode = TIM_COUNTERMODE_UP;
  htim8.Init.Period = 65535;
  htim8.Init.ClockDivision = TIM_CLOCKDIVISION_DIV1;
  htim8.Init.RepetitionCounter = 0;
  htim8.Init.AutoReloadPreload = TIM_AUTORELOAD_PRELOAD_DISABLE;
  if (HAL_TIM_Base_Init(&htim8) != HAL_OK)
  {
    Error_Handler();
  }
  sClockSourceConfig.ClockSource = TIM_CLOCKSOURCE_INTERNAL;
  if (HAL_TIM_ConfigClockSource(&htim8, &sClockSourceConfig) != HAL_OK)
  {
    Error_Handler();
  }
  if (HAL_TIM_OC_Init(&htim8) != HAL_OK)
  {
    Error_Handler();
  }
  sMasterConfig.MasterOutputTrigger = TIM_TRGO_RESET;
  sMasterConfig.MasterOutputTrigger2 = TIM_TRGO2_RESET;
  sMasterConfig.MasterSlaveMode = TIM_MASTERSLAVEMODE_DISABLE;
  if (HAL_TIMEx_MasterConfigSynchronization(&htim8, &sMasterConfig) != HAL_OK)
  {
    Error_Handler();
  }
  sConfigOC.OCMode = TIM_OCMODE_TIMING;
  sConfigOC.Pulse = 0;
  sConfigOC.OCPolarity = TIM_OCPOLARITY_HIGH;
  sConfigOC.OCFastMode = TIM_OCFAST_DISABLE;
  sConfigOC.OCIdleState = TIM_OCIDLESTATE_RESET;
  sConfigOC.OCNIdleState = TIM_OCNIDLESTATE_RESET;
  if (HAL_TIM_OC_ConfigChannel(&htim8, &sConfigOC, TIM_CHANNEL_4) != HAL_OK)
  {
    Error_Handler();
  }
  sBreakDeadTimeConfig.OffStateRunMode = TIM_OSSR_DISABLE;
  sBreakDeadTimeConfig.OffStateIDLEMode = TIM_OSSI_DISABLE;
  sBreakDeadTimeConfig.LockLevel = TIM_LOCKLEVEL_OFF;
  sBreakDeadTimeConfig.DeadTime = 0;
  sBreakDeadTimeConfig.BreakState = TIM_BREAK_DISABLE;
  sBreakDeadTimeConfig.BreakPolarity = TIM_BREAKPOLARITY_HIGH;
  sBreakDeadTimeConfig.BreakFilter = 0;
  sBreakDeadTimeConfig.Break2State = TIM_BREAK2_DISABLE;
  sBreakDeadTimeConfig.Break2Polarity = TIM_BREAK2POLARITY_HIGH;
  sBreakDeadTimeConfig.Break2Filter = 0;
  sBreakDeadTimeConfig.AutomaticOutput = TIM_AUTOMATICOUTPUT_DISABLE;
  if (HAL_TIMEx_ConfigBreakDeadTime(&htim8, &sBreakDeadTimeConfig) != HAL_OK)
  {
    Error_Handler();
  }
  HAL_TIM_MspPostInit(&htim8);

}

static void MX_UART4_Init(void)
{

  huart4.Instance = UART4;
  huart4.Init.BaudRate = 115200;
  huart4.Init.WordLength = UART_WORDLENGTH_8B;
  huart4.Init.StopBits = UART_STOPBITS_1;
  huart4.Init.Parity = UART_PARITY_NONE;
  huart4.Init.Mode = UART_MODE_TX_RX;
  huart4.Init.HwFlowCtl = UART_HWCONTROL_NONE;
  huart4.Init.OverSampling = UART_OVERSAMPLING_16;
  huart4.Init.OneBitSampling = UART_ONE_BIT_SAMPLE_DISABLE;
  huart4.AdvancedInit.AdvFeatureInit = UART_ADVFEATURE_NO_INIT;
  if (HAL_UART_Init(&huart4) != HAL_OK)
  {
    Error_Handler();
  }

}

static void MX_USART1_UART_Init(void)
{

  huart1.Instance = USART1;
  huart1.Init.BaudRate = 115200;
  huart1.Init.WordLength = UART_WORDLENGTH_8B;
  huart1.Init.StopBits = UART_STOPBITS_1;
  huart1.Init.Parity = UART_PARITY_NONE;
  huart1.Init.Mode = UART_MODE_TX_RX;
  huart1.Init.HwFlowCtl = UART_HWCONTROL_NONE;
  huart1.Init.OverSampling = UART_OVERSAMPLING_16;
  huart1.Init.OneBitSampling = UART_ONE_BIT_SAMPLE_DISABLE;
  huart1.AdvancedInit.AdvFeatureInit = UART_ADVFEATURE_NO_INIT;
  if (HAL_UART_Init(&huart1) != HAL_OK)
  {
    Error_Handler();
  }

}

static void MX_USART2_UART_Init(void)
{

  huart2.Instance = USART2;
  huart2.Init.BaudRate = 115200;
  huart2.Init.WordLength = UART_WORDLENGTH_8B;
  huart2.Init.StopBits = UART_STOPBITS_1;
  huart2.Init.Parity = UART_PARITY_NONE;
  huart2.Init.Mode = UART_MODE_TX_RX;
  huart2.Init.HwFlowCtl = UART_HWCONTROL_NONE;
  huart2.Init.OverSampling = UART_OVERSAMPLING_16;
  huart2.Init.OneBitSampling = UART_ONE_BIT_SAMPLE_DISABLE;
  huart2.AdvancedInit.AdvFeatureInit = UART_ADVFEATURE_NO_INIT;
  if (HAL_UART_Init(&huart2) != HAL_OK)
  {
    Error_Handler();
  }

}

static void MX_USART3_UART_Init(void)
{

  huart3.Instance = USART3;
  huart3.Init.BaudRate = 115200;
  huart3.Init.WordLength = UART_WORDLENGTH_8B;
  huart3.Init.StopBits = UART_STOPBITS_1;
  huart3.Init.Parity = UART_PARITY_NONE;
  huart3.Init.Mode = UART_MODE_TX_RX;
  huart3.Init.HwFlowCtl = UART_HWCONTROL_NONE;
  huart3.Init.OverSampling = UART_OVERSAMPLING_16;
  huart3.Init.OneBitSampling = UART_ONE_BIT_SAMPLE_DISABLE;
  huart3.AdvancedInit.AdvFeatureInit = UART_ADVFEATURE_NO_INIT;
  if (HAL_UART_Init(&huart3) != HAL_OK)
  {
    Error_Handler();
  }

}

static void MX_USART6_UART_Init(void)
{

  huart6.Instance = USART6;
  huart6.Init.BaudRate = 115200;
  huart6.Init.WordLength = UART_WORDLENGTH_8B;
  huart6.Init.StopBits = UART_STOPBITS_1;
  huart6.Init.Parity = UART_PARITY_NONE;
  huart6.Init.Mode = UART_MODE_TX_RX;
  huart6.Init.HwFlowCtl = UART_HWCONTROL_NONE;
  huart6.Init.OverSampling = UART_OVERSAMPLING_16;
  huart6.Init.OneBitSampling = UART_ONE_BIT_SAMPLE_DISABLE;
  huart6.AdvancedInit.AdvFeatureInit = UART_ADVFEATURE_NO_INIT;
  if (HAL_UART_Init(&huart6) != HAL_OK)
  {
    Error_Handler();
  }

}

static void MX_DMA_Init(void)
{

  /* DMA controller clock enable */
  __HAL_RCC_DMA2_CLK_ENABLE();
  __HAL_RCC_DMA1_CLK_ENABLE();

  /* DMA interrupt init */
  /* DMA1_Stream0_IRQn interrupt configuration */
  HAL_NVIC_SetPriority(DMA1_Stream0_IRQn, 0, 0);
  HAL_NVIC_EnableIRQ(DMA1_Stream0_IRQn);
  /* DMA1_Stream2_IRQn interrupt configuration */
  HAL_NVIC_SetPriority(DMA1_Stream2_IRQn, 0, 0);
  HAL_NVIC_EnableIRQ(DMA1_Stream2_IRQn);
  /* DMA1_Stream5_IRQn interrupt configuration */
  HAL_NVIC_SetPriority(DMA1_Stream5_IRQn, 0, 0);
  HAL_NVIC_EnableIRQ(DMA1_Stream5_IRQn);
  /* DMA1_Stream6_IRQn interrupt configuration */
  HAL_NVIC_SetPriority(DMA1_Stream6_IRQn, 0, 0);
  HAL_NVIC_EnableIRQ(DMA1_Stream6_IRQn);
  /* DMA1_Stream7_IRQn interrupt configuration */
  HAL_NVIC_SetPriority(DMA1_Stream7_IRQn, 0, 0);
  HAL_NVIC_EnableIRQ(DMA1_Stream7_IRQn);
  /* DMA2_Stream0_IRQn interrupt configuration */
  NVIC_SetPriority(DMA2_Stream0_IRQn, NVIC_EncodePriority(NVIC_GetPriorityGrouping(),0, 0));
  NVIC_EnableIRQ(DMA2_Stream0_IRQn);
  /* DMA2_Stream1_IRQn interrupt configuration */
  HAL_NVIC_SetPriority(DMA2_Stream1_IRQn, 0, 0);
  HAL_NVIC_EnableIRQ(DMA2_Stream1_IRQn);
  /* DMA2_Stream2_IRQn interrupt configuration */
  HAL_NVIC_SetPriority(DMA2_Stream2_IRQn, 0, 0);
  HAL_NVIC_EnableIRQ(DMA2_Stream2_IRQn);
  /* DMA2_Stream3_IRQn interrupt configuration */
  NVIC_SetPriority(DMA2_Stream3_IRQn, NVIC_EncodePriority(NVIC_GetPriorityGrouping(),0, 0));
  NVIC_EnableIRQ(DMA2_Stream3_IRQn);
  /* DMA2_Stream5_IRQn interrupt configuration */
  HAL_NVIC_SetPriority(DMA2_Stream5_IRQn, 0, 0);
  HAL_NVIC_EnableIRQ(DMA2_Stream5_IRQn);
  /* DMA2_Stream6_IRQn interrupt configuration */
  HAL_NVIC_SetPriority(DMA2_Stream6_IRQn, 0, 0);
  HAL_NVIC_EnableIRQ(DMA2_Stream6_IRQn);
  /* DMA2_Stream7_IRQn interrupt configuration */
  HAL_NVIC_SetPriority(DMA2_Stream7_IRQn, 0, 0);
  HAL_NVIC_EnableIRQ(DMA2_Stream7_IRQn);

}

static void MX_GPIO_Init(void)
{
  LL_GPIO_InitTypeDef GPIO_InitStruct = {0};

  /* GPIO Ports Clock Enable */
  LL_AHB1_GRP1_EnableClock(LL_AHB1_GRP1_PERIPH_GPIOH);
  LL_AHB1_GRP1_EnableClock(LL_AHB1_GRP1_PERIPH_GPIOC);
  LL_AHB1_GRP1_EnableClock(LL_AHB1_GRP1_PERIPH_GPIOA);
  LL_AHB1_GRP1_EnableClock(LL_AHB1_GRP1_PERIPH_GPIOB);
  LL_AHB1_GRP1_EnableClock(LL_AHB1_GRP1_PERIPH_GPIOD);

  /**/
  LL_GPIO_ResetOutputPin(IMU_CS_GPIO_Port, IMU_CS_Pin);

  /**/
  LL_GPIO_ResetOutputPin(BARO_CS_GPIO_Port, BARO_CS_Pin);

  /**/
  LL_GPIO_ResetOutputPin(RGB_R_GPIO_Port, RGB_R_Pin);

  /**/
  LL_GPIO_ResetOutputPin(RGB_G_GPIO_Port, RGB_G_Pin);

  /**/
  LL_GPIO_ResetOutputPin(RGB_B_GPIO_Port, RGB_B_Pin);

  /**/
  LL_GPIO_ResetOutputPin(SPI2_CS2_GPIO_Port, SPI2_CS2_Pin);

  /**/
  LL_GPIO_ResetOutputPin(SPI2_CS1_GPIO_Port, SPI2_CS1_Pin);

  /**/
  GPIO_InitStruct.Pin = IMU_CS_Pin;
  GPIO_InitStruct.Mode = LL_GPIO_MODE_OUTPUT;
  GPIO_InitStruct.Speed = LL_GPIO_SPEED_FREQ_LOW;
  GPIO_InitStruct.OutputType = LL_GPIO_OUTPUT_PUSHPULL;
  GPIO_InitStruct.Pull = LL_GPIO_PULL_NO;
  LL_GPIO_Init(IMU_CS_GPIO_Port, &GPIO_InitStruct);

  /**/
  GPIO_InitStruct.Pin = BARO_CS_Pin;
  GPIO_InitStruct.Mode = LL_GPIO_MODE_OUTPUT;
  GPIO_InitStruct.Speed = LL_GPIO_SPEED_FREQ_LOW;
  GPIO_InitStruct.OutputType = LL_GPIO_OUTPUT_PUSHPULL;
  GPIO_InitStruct.Pull = LL_GPIO_PULL_NO;
  LL_GPIO_Init(BARO_CS_GPIO_Port, &GPIO_InitStruct);

  /**/
  GPIO_InitStruct.Pin = RGB_R_Pin;
  GPIO_InitStruct.Mode = LL_GPIO_MODE_OUTPUT;
  GPIO_InitStruct.Speed = LL_GPIO_SPEED_FREQ_LOW;
  GPIO_InitStruct.OutputType = LL_GPIO_OUTPUT_PUSHPULL;
  GPIO_InitStruct.Pull = LL_GPIO_PULL_NO;
  LL_GPIO_Init(RGB_R_GPIO_Port, &GPIO_InitStruct);

  /**/
  GPIO_InitStruct.Pin = RGB_G_Pin;
  GPIO_InitStruct.Mode = LL_GPIO_MODE_OUTPUT;
  GPIO_InitStruct.Speed = LL_GPIO_SPEED_FREQ_LOW;
  GPIO_InitStruct.OutputType = LL_GPIO_OUTPUT_PUSHPULL;
  GPIO_InitStruct.Pull = LL_GPIO_PULL_NO;
  LL_GPIO_Init(RGB_G_GPIO_Port, &GPIO_InitStruct);

  /**/
  GPIO_InitStruct.Pin = RGB_B_Pin;
  GPIO_InitStruct.Mode = LL_GPIO_MODE_OUTPUT;
  GPIO_InitStruct.Speed = LL_GPIO_SPEED_FREQ_LOW;
  GPIO_InitStruct.OutputType = LL_GPIO_OUTPUT_PUSHPULL;
  GPIO_InitStruct.Pull = LL_GPIO_PULL_NO;
  LL_GPIO_Init(RGB_B_GPIO_Port, &GPIO_InitStruct);

  /**/
  GPIO_InitStruct.Pin = Card_Detect_Pin;
  GPIO_InitStruct.Mode = LL_GPIO_MODE_INPUT;
  GPIO_InitStruct.Pull = LL_GPIO_PULL_NO;
  LL_GPIO_Init(Card_Detect_GPIO_Port, &GPIO_InitStruct);

  /**/
  GPIO_InitStruct.Pin = SPI2_CS2_Pin;
  GPIO_InitStruct.Mode = LL_GPIO_MODE_OUTPUT;
  GPIO_InitStruct.Speed = LL_GPIO_SPEED_FREQ_LOW;
  GPIO_InitStruct.OutputType = LL_GPIO_OUTPUT_PUSHPULL;
  GPIO_InitStruct.Pull = LL_GPIO_PULL_NO;
  LL_GPIO_Init(SPI2_CS2_GPIO_Port, &GPIO_InitStruct);

  /**/
  GPIO_InitStruct.Pin = SPI2_CS1_Pin;
  GPIO_InitStruct.Mode = LL_GPIO_MODE_OUTPUT;
  GPIO_InitStruct.Speed = LL_GPIO_SPEED_FREQ_LOW;
  GPIO_InitStruct.OutputType = LL_GPIO_OUTPUT_PUSHPULL;
  GPIO_InitStruct.Pull = LL_GPIO_PULL_NO;
  LL_GPIO_Init(SPI2_CS1_GPIO_Port, &GPIO_InitStruct);

}

 /* MPU Configuration */

void MPU_Config(void)
{
  MPU_Region_InitTypeDef MPU_InitStruct = {0};

  /* Disables the MPU */
  HAL_MPU_Disable();

  /** Initializes and configures the Region and the memory to be protected
  */
  MPU_InitStruct.Enable = MPU_REGION_ENABLE;
  MPU_InitStruct.Number = MPU_REGION_NUMBER0;
  MPU_InitStruct.BaseAddress = 0x0;
  MPU_InitStruct.Size = MPU_REGION_SIZE_4GB;
  MPU_InitStruct.SubRegionDisable = 0x87;
  MPU_InitStruct.TypeExtField = MPU_TEX_LEVEL0;
  MPU_InitStruct.AccessPermission = MPU_REGION_NO_ACCESS;
  MPU_InitStruct.DisableExec = MPU_INSTRUCTION_ACCESS_DISABLE;
  MPU_InitStruct.IsShareable = MPU_ACCESS_SHAREABLE;
  MPU_InitStruct.IsCacheable = MPU_ACCESS_NOT_CACHEABLE;
  MPU_InitStruct.IsBufferable = MPU_ACCESS_NOT_BUFFERABLE;

  HAL_MPU_ConfigRegion(&MPU_InitStruct);
  /* Enables the MPU */
  HAL_MPU_Enable(MPU_PRIVILEGED_DEFAULT);

}

void Error_Handler(void)
{
  __disable_irq();
  while (1)
  {
  }
}
